# R40 register map
Vendor: Allwinner; Series: R40; File version: 0.1
CPU: CA7 0, little endian, MPU, FPU, double-precision FPU, 0 interrupt priority bits
Registers are 32-bit, read-write, reset 0x0 unless marked. A register's access mark holds for its fields unless they carry their own. Offsets are from the block's base; [hi:lo] are bit positions; lines under a group give offsets from that group; {n}, {i} and the like mark numbered series; 'fields as' and 'values as' point back to an identical list; <NAME> marks a mode.

## MP
Base 0x01E80000
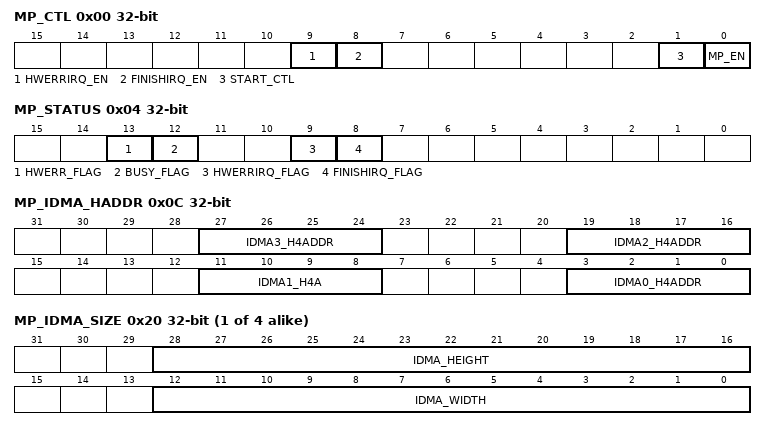
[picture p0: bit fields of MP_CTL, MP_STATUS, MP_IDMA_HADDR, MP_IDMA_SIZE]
0x00 MP_CTL
  [9] HWERRIRQ_EN — Hardware error IRQ enable control 0:Disable 1:Enable
  [8] FINISHIRQ_EN — Mission finish IRQ enable control 0:Disable 1:Enable
  [1] START_CTL — Start control If the bit is set, the module will start 1 frame operation and stop automatically.
  [0] MP_EN — Enable control 0:Disable 1:Enable
0x04 MP_STATUS
  [13] HWERR_FLAG ro — Hardware error status
  [12] BUSY_FLAG ro — Module working status 0:Idle 1:Running
  [9] HWERRIRQ_FLAG — Hardware error IRQ It will be set when hardware error occurs, and cleared by writing 1.
  [8] FINISHIRQ_FLAG — Mission finish IRQ It will be set when 1 frame operation accomplished, and cleared by writing 1.
0x08 MP_DMA_ORDER
  [9:8] MEMSCANORDER — Memory scan order selection 00: Top to down, Left to right 01: Top to down, Right to left 10: Down to top, Left to right 11: Down to top, Right to left Note: Four input DMA channel use the same scan rule. The each output DMA channel should match the same memory scan order rule with the input DMA channel.
    0=Top_to_down_comma__Left (Top to down, Left to right); 1=Top_to_down_comma__Right (Top to down, Right to left); 2=Down_to_top_comma__Left (Down to top, Left to right); 3=Down_to_top_comma__Right (Down to top, Right to left Note: Four input DMA channel use the same scan rule. The each output DMA channel should match the same memory scan order rule with the input DMA channel.)
0x0C MP_IDMA_HADDR
  [27:24] IDMA3_H4ADDR — High 4bit address in bit
  [19:16] IDMA2_H4ADDR — High 4bit address in bit
  [11:8] IDMA1_H4A — High 4bit address in bit
  [3:0] IDMA0_H4ADDR — High 4bit address in bit
{0x10+4i} _N[{i}] (i=0..3) group
  0x00 MP_IDMA_LADDR
    [31:0] IDMA_L32ADDR — Low 32bit address in bit
  0x10 MP_IDMA_PITCH
    [31:0] IDMA_PITCH — Pitch in bit
  0x20 MP_IDMA_SIZE
    [28:16] IDMA_HEIGHT — Memory block height in pixels The height = The value of these bits add 1
    [12:0] IDMA_WIDTH — Memory block width in pixels The width = The value of these bits add 1
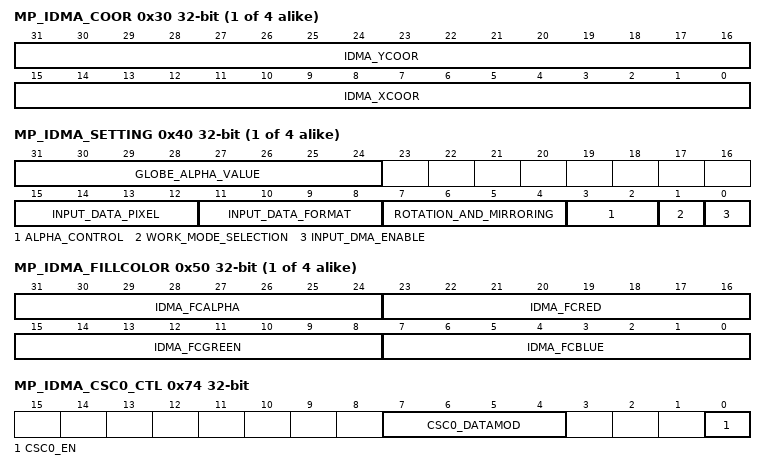
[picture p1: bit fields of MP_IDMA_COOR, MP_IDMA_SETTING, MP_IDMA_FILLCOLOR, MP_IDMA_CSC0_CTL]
  0x30 MP_IDMA_COOR
    [31:16] IDMA_YCOOR — Y coordinate Y is the left-top y coordinate of layer on output window in pixels The Y represent the two`s complement
    [15:0] IDMA_XCOOR — X coordinate X is left-top x coordinate of the layer on output window in pixels The X represent the two`s complement
  0x40 MP_IDMA_SETTING
    [31:24] GLOBE_ALPHA_VALUE
    [15:12] INPUT_DATA_PIXEL — Input data pixel sequence Reference input pixel sequence table
    [11:8] INPUT_DATA_FORMAT — Input data format 0000:32bpp - A8R8G8B8 or interleaved AYUV8888 0001:16bpp - A4R4G4B4 0010:16bpp - A1R5G5B5 0011:16bpp - R5G6B5 0100:16bpp - interleaved YUV422 0101:16bpp - U8V8 0110:8bpp - Y8 0111:8bpp - MONO or palette 1000:4bpp - MONO or palette 1001:2bpp - MONO or palette 1010:1bpp - MONO or palette Other: reserved Note: If the input data format is 16 or 32bpp, and the work mode is palette mode, only the low 8 bits input data is valid.
    [7:4] ROTATION_AND_MIRRORING — Rotation and mirroring control 0000:normal 0001:X 0010:Y 0011:XY 0100:A 0101:AX 0110:AY 0111:AXY Other: reserved
    [3:2] ALPHA_CONTROL — Alpha control 0:Ignore Output alpha value = pixels alpha, if no pixel alpha, the alpha value equal 0xff 01:Globe alpha enable Ignore pixel alpha value Output alpha value = globe alpha value 10: Globe alpha mix pixel alpha Output alpha value = globe alpha value * pixels alpha value 11:Reserved Note: The output alpha value here means the input alpha value of the ALU following the DMA controller.
      2=Globe alpha mix pixel alpha Output alpha value = globe alpha value * pixels alpha value 11:Reserved Note: The output alpha value here means the input alpha value of the ALU following the DMA controller
    [1] WORK_MODE_SELECTION — Work mode selection 0: normal mode ( non-palette mode ) 1: palette mode
      0=normal mode ( non-palette mode ); 1=palette_mode
    [0] INPUT_DMA_ENABLE — Input DMA enable control 0:disable input DMA channel, the respective fill-color value will stead of the input data. 1:enable
  0x50 MP_IDMA_FILLCOLOR
    [31:24] IDMA_FCALPHA — Alpha
    [23:16] IDMA_FCRED — Red
    [15:8] IDMA_FCGREEN — Green
    [7:0] IDMA_FCBLUE — Blue
0x74 MP_IDMA_CSC0_CTL
  [7:4] CSC0_DATAMOD — Data mode control 0000: Interleaved AYUV8888 mode 0001: Interleaved YUV422 mode In mode 0 and mode 1, only the channel 0 data path is valid for this module, the channel 1 data flow will by-pass the csc0 module, and direct to input formatter 1. 0010: Planar YUV422 mode (UV combined only) 0011: Planar YUV420 mode (UV combined only) 0100: Planar YUV411 mode (UV combined only) In mode 2/3/4, following rule: In this mode, the output data of the input formatter 1 will be stead of the respective fill-color value.
    0=Interleaved_AYUV8888_mode; 1=Interleaved YUV422 mode In mode 0 and mode 1, only the channel 0 data path is valid for this module, the channel 1 data flow will by-pass the csc0 module, and direct to input formatter 1; 2=Planar YUV422 mode (UV combined only); 3=Planar YUV420 mode (UV combined only); 4=Planar YUV411 mode (UV combined only) In mode 2/3/4, following rule: In this mode, the output data of the input formatter 1 will be stead of the respective fill-color value
  [0] CSC0_EN — Enable control 0: Disable color space function, ignore the control setting, and the data flow will by-pass the module. 1: Enable color space converting function.
    0=Disable color space function, ignore the control setting, and the data flow will by-pass the module; 1=Enable color space converting function
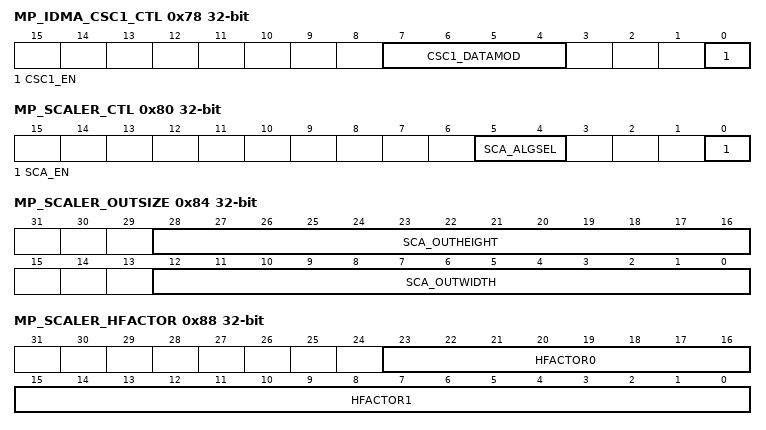
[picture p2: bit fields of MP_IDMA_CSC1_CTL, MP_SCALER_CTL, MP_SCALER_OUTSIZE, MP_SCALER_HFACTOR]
0x78 MP_IDMA_CSC1_CTL
  [7:4] CSC1_DATAMOD — Data mode control 0000: Interleaved AYUV8888 mode 0001: Interleaved YUV422 mode In mode 0 and mode 1, only the channel 3 data path is valid for this module, the channel 2 data flow will by-pass the csc1 module, and direct to input formatter 2. 0010: Planar YUV422 mode (UV combined only) 0011: Planar YUV420 mode (UV combined only) 0100: Planar YUV411 mode (UV combined only) In mode 2/3/4, following rule: In this mode, the output data of the input formatter 2 will be stead of the respective fill-color value.
    0=Interleaved_AYUV8888_mode; 1=Interleaved YUV422 mode In mode 0 and mode 1, only the channel 3 data path is valid for this module, the channel 2 data flow will by-pass the csc1 module, and direct to input formatter 2; 2=Planar YUV422 mode (UV combined only); 3=Planar YUV420 mode (UV combined only); 4=Planar YUV411 mode (UV combined only) In mode 2/3/4, following rule: In this mode, the output data of the input formatter 2 will be stead of the respective fill-color value
  [0] CSC1_EN — Enable control 0: Disable color space function, ignore the control setting, and the data flow will by-pass the module. 1: Enable color space converting function.
    values as MP_IDMA_CSC0_CTL.CSC0_EN
0x80 MP_SCALER_CTL
  [5:4] SCA_ALGSEL — Scaling algorithm selection 00: bi-cubic(4 taps in vertical and horizontal) 01: linear in vertical and bi-linear in horizontal(2 taps in vertical and 4 taps in horizontal) 10: extractive in vertical and bi-linear in horizontal(1 tap in vertical and 4 taps in horizontal) 11: Reserved
    0=bicubic_openingparen_4 (bi-cubic(4 taps in vertical and horizontal)); 1=linear in vertical and bi-linear in horizontal(2 taps in vertical and 4 taps in horizontal); 2=extractive in vertical and bi-linear in horizontal(1 tap in vertical and 4 taps in horizontal)
  [0] SCA_EN — Enable control 0: Disable scaler, ignore the whole scaling setting, and the data flow will by-pass the module. 1: Enable scaling function
    0=Disable scaler, ignore the whole scaling setting, and the data flow will by-pass the module; 1=Enable scaling function
0x84 MP_SCALER_OUTSIZE
  [28:16] SCA_OUTHEIGHT — Output height The output height = The value of these bits add 1 The minimum output height is 8 pixels.
  [12:0] SCA_OUTWIDTH — Output width The output width = The value of these bits add 1 The minimum output width is 16 pixels.
0x88 MP_SCALER_HFACTOR
  [23:16] HFACTOR0 — The integer part of the horizontal scaling ratio the horizontal scaling ratio = input width/output width
  [15:0] HFACTOR1 — The fractional part of the horizontal scaling ratio the horizontal scaling ratio = input width/output width The input width is the memory block width of respective iDMA channel.
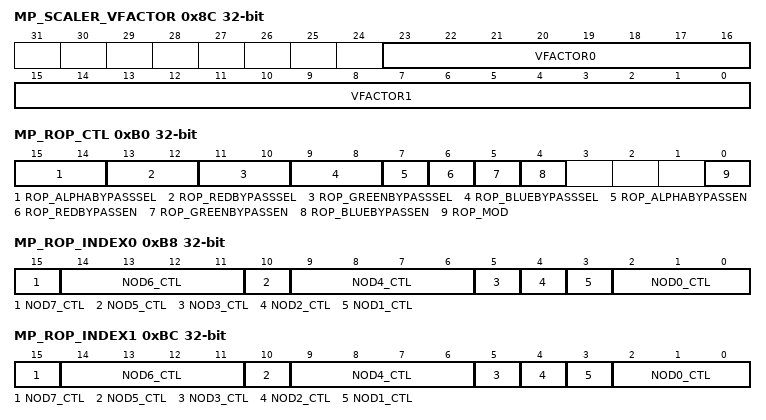
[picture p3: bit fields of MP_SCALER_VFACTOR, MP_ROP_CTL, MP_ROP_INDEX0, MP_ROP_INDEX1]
0x8C MP_SCALER_VFACTOR
  [23:16] VFACTOR0 — The integer part of the vertical scaling ratio the vertical scaling ratio = input height/output height
  [15:0] VFACTOR1 — The fractional part of the vertical scaling ratio the vertical scaling ratio = input height /output height The input height is the memory block height of respective iDMA channel.
0x90 MP_SCALER_HPHASE
  [19:0] HPHASE — Start phase in horizontal (complement) This value equals to start phase * 2
0x94 MP_SCALER_VPHASE
  [19:0] SCA_VERPHASE — Start phase in vertical (complement) This value equals to start phase * 2
0xB0 MP_ROP_CTL
  [15:14] ROP_ALPHABYPASSSEL — ROP output Alpha channel selection 00: Channel 0 01: Channel 1 10: Channel 2 11: Reserved The bit is only valid in by-pass mode of Alpha channel
    0=Channel_0; 1=Channel_1; 2=Channel_2
  [13:12] ROP_REDBYPASSSEL — ROP output Red channel selection 00: Channel 0 01: Channel 1 10: Channel 2 11: Reserved The bit is only valid in by-pass mode of Red channel
    0=Channel_0; 1=Channel_1; 2=Channel_2
  [11:10] ROP_GREENBYPASSSEL — ROP output Green channel selection 00: Channel 0 01: Channel 1 10: Channel 2 11: Reserved The bit is only valid in by-pass mode of Green channel
    0=Channel_0; 1=Channel_1; 2=Channel_2
  [9:8] ROP_BLUEBYPASSSEL — ROP output Blue channel selection 00: Channel 0 01: Channel 1 10: Channel 2 11: Reserved The bit is only valid in by-pass mode of Blue channel
    0=Channel_0; 1=Channel_1; 2=Channel_2
  [7] ROP_ALPHABYPASSEN — ROP Alpha channel by-pass enable control 0: Pass through 1: By-pass
    0=Pass through; 1=bypass
  [6] ROP_REDBYPASSEN — ROP Red channel by-pass enable control 0: Pass through 1: By-pass
    0=Pass through; 1=bypass
  [5] ROP_GREENBYPASSEN — ROP Green channel by-pass enable control 0: Pass through 1: By-pass
    0=Pass through; 1=bypass
  [4] ROP_BLUEBYPASSEN — ROP Blue channel by-pass enable control 0: Pass through 1: By-pass
    0=Pass through; 1=bypass
  [0] ROP_MOD — ROP type selection 0: ROP3 1: ROP4 In ROP3 mode, only the value of channel 3 index 0 control table setting register will be selected. In ROP3 mode, the channel 3 data will by-pass the ROP module. In ROP3 mode, the channel 3 data will direct to Alpha/CK module. In ROP4 mode, the respective input DMA channel fill color of channel 3 will transfer to Alpha/CK module.
    0=ROP3; 1=ROP4 (ROP4 In ROP3 mode, only the value of channel 3 index 0 control table setting register will be selected. In ROP3 mode, the channel 3 data will by-pass the ROP module. In ROP3 mode, the channel 3 data will direct to Alpha/CK module. In ROP4 mode, the respective input DMA channel fill color of channel 3 will transfer to Alpha/CK module.)
0xB8 MP_ROP_INDEX0
  [15] NOD7_CTL — Index 0 node7 setting ( channel 0` and channel 1` and channel 2` mix not logic ) 0: By-pass 1: Not
    0=bypass; 1=Not
  [14:11] NOD6_CTL — Index 0 node6 setting ( channel 0` and channel 1` and channel 2` mix logic ) 0000: And 0001: OR 0010: XOR 0011: Add in byte 0100: Add in word (32bit) 0101: Multiply in byte 0110: Multiply in word (32bit) 0111: Channel 0` mix channel 1` then sub channel 2` in byte 1000: Channel 0` mix channel 1` then sub channel 2` in word (32bit) Other: Reserved
  [10] NOD5_CTL — Index 0 node5 setting ( channel 0` and channel 1` mix not logic ) 0: By-pass 1: Not
    0=bypass; 1=Not
  [9:6] NOD4_CTL — Index 0 node4 setting ( channel 0` and channel 1` mix logic ) 0000: And 0001: OR 0010: XOR 0011: Add in byte 0100: Add in word (32bit) 0101: Multiply in byte 0110: Multiply in word (32bit) 0111: Channel 0` sub channel 1` in byte 1000: Channel 0` sub channel 1` in word (32bit) Other: Reserved
  [5] NOD3_CTL — Index 0 node3 setting ( channel 2` not logic ) 0: By-pass 1: Not
    0=bypass; 1=Not
  [4] NOD2_CTL — Index 0 node2 setting ( channel 1` not logic ) 0: By-pass 1: Not
    0=bypass; 1=Not
  [3] NOD1_CTL — Index 0 node1 setting ( channel 0` not logic) 0: By-pass 1: Not
    0=bypass; 1=Not
  [2:0] NOD0_CTL — Index 0 node0 setting ( sorting control ) 000: 012 001: 021 010: 102 011: 120 100: 201 101: 210 Other: Reserved
    0=_012; 1=_021; 2=_102; 3=_120; 4=_201; 5=210 Other: Reserved
0xBC MP_ROP_INDEX1
  [15] NOD7_CTL — Index 1 node7 setting ( channel 0` and channel 1` and channel 2` mix not logic ) 0: By-pass 1: Not
    0=bypass; 1=Not
  [14:11] NOD6_CTL — Index 1 node6 setting ( channel 0` and channel 1` and channel 2` mix logic ) 0000: And 0001: OR 0010: XOR 0011: Add in byte 0100: Add in word (32bit) 0101: Multiply in byte 0110: Multiply in word (32bit) 0111: Channel 0` mix channel 1` then sub channel 2` in byte 1000: Channel 0` mix channel 1` then sub channel 2` in word (32bit) Other: Reserved
  [10] NOD5_CTL — Index 1 node5 setting ( channel 0` and channel 1` mix not logic ) 0: By-pass 1: Not
    0=bypass; 1=Not
  [9:6] NOD4_CTL — Index 1 node4 setting ( channel 0` and channel 1` mix logic ) 0000: And 0001: OR 0010: XOR 0011: Add in byte 0100: Add in word (32bit) 0101: Multiply in byte 0110: Multiply in word (32bit) 0111: Channel 0` sub channel 1` in byte 1000: Channel 0` sub channel 1` in word (32bit) Other: Reserved
  [5] NOD3_CTL — Index 1 node3 setting ( channel 2` not logic ) 0: By-pass 1: Not
    0=bypass; 1=Not
  [4] NOD2_CTL — Index 1 node2 setting ( channel 1` not logic ) 0: By-pass 1: Not
    0=bypass; 1=Not
  [3] NOD1_CTL — Index 1 node1 setting ( channel 0` not logic) 0: By-pass 1: Not
    0=bypass; 1=Not
  [2:0] NOD0_CTL — Index 1 node0 setting ( sorting control ) 000: 012 001: 021 010: 102 011: 120 100: 201 101: 210 Other: Reserved
    values as MP_ROP_INDEX0.NOD0_CTL
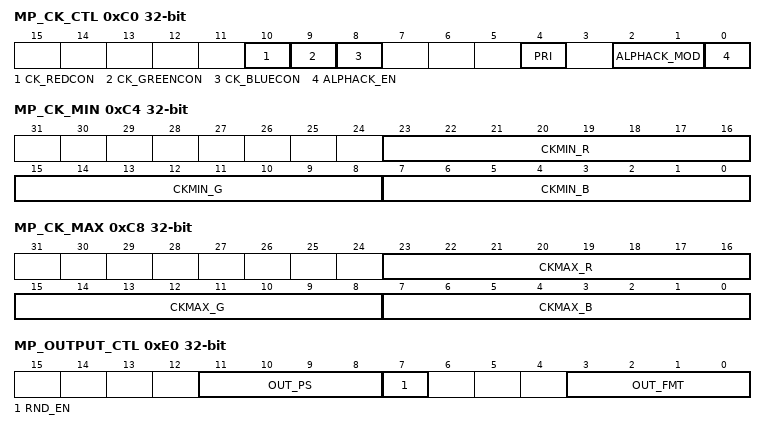
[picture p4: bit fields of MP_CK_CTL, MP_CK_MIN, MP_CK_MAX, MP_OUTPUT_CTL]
0xC0 MP_CK_CTL
  [10] CK_REDCON — Red control condition 0: If (R value of ck min color) <= (R value of layer0) <= (R value of ck max color), The red control condition is true, else the condition is false. 1: If (R value of ck min color) > (R value of layer0) or (R value of layer0) > (R value of ck max color), The red control condition is true, else the condition is false.
    0=If__openingparen_R_value_of_ck_min_color_closingparen___lt__equals_ (If (R value of ck min color) <= (R value of layer0) <= (R value of ck max color), The red control condition is true, else the condition is false.); 1=If__openingparen_R_value_of_ck_min_color_closingparen___gt_ (If (R value of ck min color) > (R value of layer0) or (R value of layer0) > (R value of ck max color), The red control condition is true, else the condition is false.)
  [9] CK_GREENCON — Green control condition 0: If (G value of ck min color) <= (G value of layer0) <= (G value of ck max color), The green control condition is true, else the condition is false. 1: If (G value of ck min color) > (G value of layer0) or (G value of layer0) > (G value of ck max color), The green control condition is true, else the condition is false.
    0=If__openingparen_G_value_of_ck_min_color_closingparen___lt__equals_ (If (G value of ck min color) <= (G value of layer0) <= (G value of ck max color), The green control condition is true, else the condition is false.); 1=If__openingparen_G_value_of_ck_min_color_closingparen___gt_ (If (G value of ck min color) > (G value of layer0) or (G value of layer0) > (G value of ck max color), The green control condition is true, else the condition is false.)
  [8] CK_BLUECON — Blue control condition 0: If (B value of ck min color) <= (B value of layer0) <= (B value of ck max color), The blue control condition is true, else the condition is false. 1: If (B value of ck min color) > (B value of layer0) or (B value of layer0) > (B value of ck max color), The blue control condition is true, else the condition is false.
    0=If__openingparen_B_value_of_ck_min_color_closingparen___lt__equals_ (If (B value of ck min color) <= (B value of layer0) <= (B value of ck max color), The blue control condition is true, else the condition is false.); 1=If__openingparen_B_value_of_ck_min_color_closingparen___gt_ (If (B value of ck min color) > (B value of layer0) or (B value of layer0) > (B value of ck max color), The blue control condition is true, else the condition is false.)
  [4] PRI — Priority selection 0: ROP output channel is higher than channel 3 1: Channel 3 is higher than ROP output channel
    0=ROP (ROP output channel is higher than channel 3); 1=Channel 3 is higher than ROP output channel
  [2:1] ALPHACK_MOD — Alpha / Color key mode selection 00: Alpha mode 01: Color key mode, using the high priority layer as matching condition, if it is true, the low priority layer pass. 10: color key mode, using the low priority layer as matching condition, if it is true, the high priority layer pass. 11: Reserved
  [0] ALPHACK_EN — Enable control 0: The ROP data will by-pass the alpha/ck module 1: Enable If the module is disabled, the data of channel 3 will be ignored, and only the ROP data will pass through to CSC2 module.
    0=ROP_data (The ROP data will by-pass the alpha/ck module); 1=Enable If the module is disabled, the data of channel 3 will be ignored, and only the ROP data will pass through to CSC2 module
0xC4 MP_CK_MIN
  [23:16] CKMIN_R — Red
  [15:8] CKMIN_G — Green
  [7:0] CKMIN_B — Blue
0xC8 MP_CK_MAX
  [23:16] CKMAX_R — Red
  [15:8] CKMAX_G — Green
  [7:0] CKMAX_B — Blue
0xD0 MP_CSC2_CTL
  [0] CSC2_EN — Enable control 0: Disable color space function, ignore the control setting, and the data flow will by-pass the module. 1: Enable color space converting function.
    values as MP_IDMA_CSC0_CTL.CSC0_EN
0xE0 MP_OUTPUT_CTL
  [11:8] OUT_PS — Output data pixel sequence Reference output pixel sequence table
  [7] RND_EN — Round enable 0: Disabled 1: Enabled
    0=Disabled; 1=Enabled
  [3:0] OUT_FMT — Output data format 0000: 32bpp - A8R8G8B8 or interleaved AYUV8888 0001: 16bpp - A4R4G4B4 0010: 16bpp - A1R5G5B5 0011: 16bpp - R5G6B5 0100: 16bpp - interleaved YUV422 0101: planar YUV422 (UV combined) 0110: planar YUV422 0111: 8bpp - MONO 1000: 4bpp - MONO 1001: 2bpp - MONO 1010: 1bpp - MONO 1011: planar YUV420 (UV combined) 1100: planar YUV420 1101: planar YUV411 (UV combined) 1110: planar YUV411 Other: Reserved Note: In all YUV output data format, the CSC2 must be enabled, otherwise the output data mode will be 32bpp A8R8G8B8 mode.
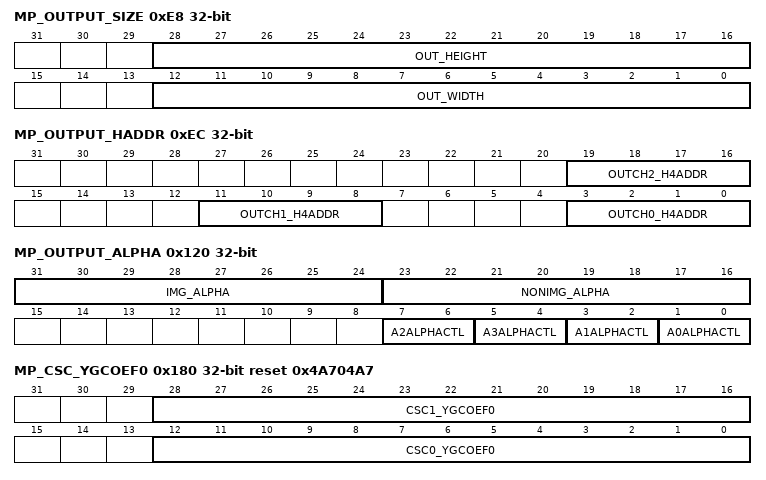
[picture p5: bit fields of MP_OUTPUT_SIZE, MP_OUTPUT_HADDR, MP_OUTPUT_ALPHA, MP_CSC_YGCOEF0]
0xE8 MP_OUTPUT_SIZE
  [28:16] OUT_HEIGHT — Height The value add 1 equal the actual output image height
  [12:0] OUT_WIDTH — Width The value add 1 equal the actual output image width
0xEC MP_OUTPUT_HADDR
  [19:16] OUTCH2_H4ADDR — Output channel 2 High 4bit address in bit
  [11:8] OUTCH1_H4ADDR — Output channel 1 High 4bit address in bit
  [3:0] OUTCH0_H4ADDR — Output channel 0 High 4bit address in bit
{0xF0+4i} _N[{i}] (i=0..2) group
  0x00 MP_OUTPUT_LADDR
    [31:0] OUT_L32ADDR — Output channel Low 32bit address in bit
  0x10 MP_OUTPUT_PITCH
    [31:0] OUT_LINEWIDTH — Output channel Pitch in bit
  0xD0 MP_OCSC_YGCOEF
    [12:0] CSC2_YGCOEF — The Y/G coefficient The value equals to coefficient*2
  0xE0 MP_OCSC_URCOEF
    [12:0] CSC2_URCOEF — The U/R coefficient The value equals to coefficient*2
  0xF0 MP_OCSC_VBCOEF
    [12:0] CSC2_VBCOEF — The V/B coefficient The value equals to coefficient*2
0x120 MP_OUTPUT_ALPHA
  [31:24] IMG_ALPHA — Output image area alpha value, the image area include A0,A1 and overlapping area A2.
  [23:16] NONIMG_ALPHA — Output non-image area alpha value, the non-image area means the pure fill color area.
  [7:6] A2ALPHACTL — A2 area alpha value control 00: using A0 self pixel alpha (A0pA) 01: using A1 self pixel alpha (A1pA) 10: the alpha value = A0pA + A1pA * ( 1 - A0pA ) 11: using the Output image area alpha value (bit31:24)
    0=A0 (using A0 self pixel alpha (A0pA)); 1=A1 (using A1 self pixel alpha (A1pA)); 2=alpha (the alpha value = A0pA + A1pA * ( 1 - A0pA )); 3=Output (using the Output image area alpha value (bit31:24))
  [5:4] A3ALPHACTL — A3 area alpha value control 00: 0xff 01: using the Output non-image area alpha value (bit23:16) Other: reserved
    0=_0xff; 1=Output (using the Output non-image area alpha value (bit23:16) Other: reserved)
  [3:2] A1ALPHACTL — A1 area alpha value control 00: using A1 self pixel alpha 01: using the Output image area alpha value (bit31:24) Other: reserved
    0=A1 (using A1 self pixel alpha); 1=Output (using the Output image area alpha value (bit31:24) Other: reserved)
  [1:0] A0ALPHACTL — A0 area alpha value control 00: using A0 self pixel alpha 01: using the Output image area alpha value (bit31:24) Other: reserved
    0=A0 (using A0 self pixel alpha); 1=Output (using the Output image area alpha value (bit31:24) Other: reserved)
0x180 MP_CSC_YGCOEF0 reset 0x4A704A7
  [28:16] CSC1_YGCOEF0 — The Y/G coefficient for CSC1 The value equals to coefficient*2
  [12:0] CSC0_YGCOEF0 — The Y/G coefficient for CSC0 The value equals to coefficient*2
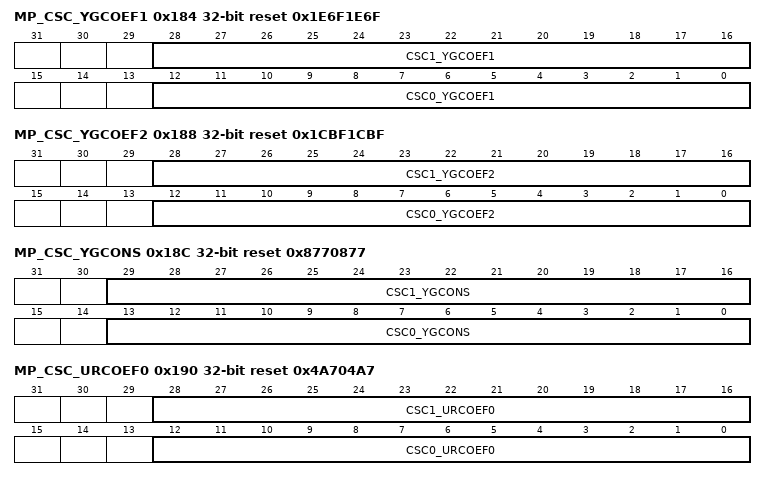
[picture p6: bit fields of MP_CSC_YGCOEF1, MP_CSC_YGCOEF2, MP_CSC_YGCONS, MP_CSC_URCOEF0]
0x184 MP_CSC_YGCOEF1 reset 0x1E6F1E6F
  [28:16] CSC1_YGCOEF1 — The Y/G coefficient for CSC1 The value equals to coefficient*2
  [12:0] CSC0_YGCOEF1 — The Y/G coefficient for CSC0 The value equals to coefficient*2
0x188 MP_CSC_YGCOEF2 reset 0x1CBF1CBF
  [28:16] CSC1_YGCOEF2 — The Y/G coefficient for CSC1 The value equals to coefficient*2
  [12:0] CSC0_YGCOEF2 — The Y/G coefficient for CSC0 The value equals to coefficient*2
0x18C MP_CSC_YGCONS reset 0x8770877
  [29:16] CSC1_YGCONS — The Y/G constant for CSC1 The value equals to coefficient*2
  [13:0] CSC0_YGCONS — The Y/G constant for CSC0 The value equals to coefficient*2
0x190 MP_CSC_URCOEF0 reset 0x4A704A7
  [28:16] CSC1_URCOEF0 — The U/R coefficient for CSC1 The value equals to coefficient*2
  [12:0] CSC0_URCOEF0 — The U/R coefficient for CSC0 The value equals to coefficient*2
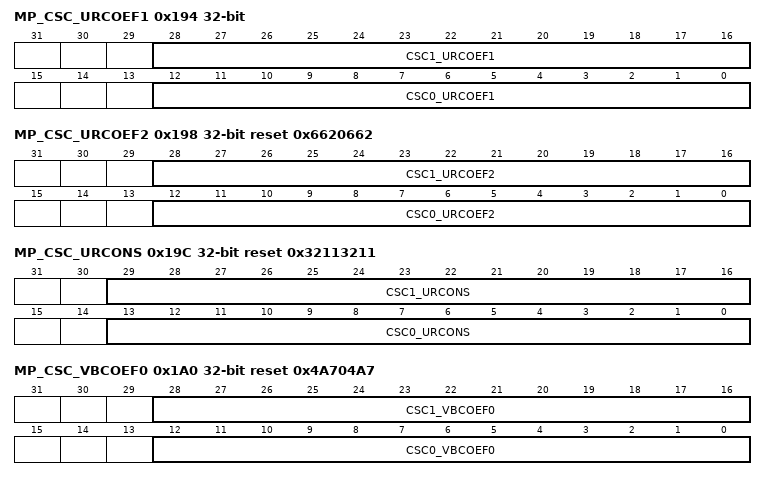
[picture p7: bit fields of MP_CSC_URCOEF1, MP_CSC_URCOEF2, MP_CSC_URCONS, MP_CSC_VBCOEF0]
0x194 MP_CSC_URCOEF1
  [28:16] CSC1_URCOEF1 — The U/R coefficient for CSC1 The value equals to coefficient*2
  [12:0] CSC0_URCOEF1 — The U/R coefficient for CSC0 The value equals to coefficient*2
0x198 MP_CSC_URCOEF2 reset 0x6620662
  [28:16] CSC1_URCOEF2 — The U/R coefficient for CSC1 The value equals to coefficient*2
  [12:0] CSC0_URCOEF2 — The U/R coefficient for CSC0 The value equals to coefficient*2
0x19C MP_CSC_URCONS reset 0x32113211
  [29:16] CSC1_URCONS — The U/R constant for CSC1 The value equals to coefficient*2
  [13:0] CSC0_URCONS — The U/R constant for CSC0 The value equals to coefficient*2
0x1A0 MP_CSC_VBCOEF0 reset 0x4A704A7
  [28:16] CSC1_VBCOEF0 — The V/B coefficient for CSC1 The value equals to coefficient*2
  [12:0] CSC0_VBCOEF0 — The V/B coefficient for CSC0 The value equals to coefficient*2
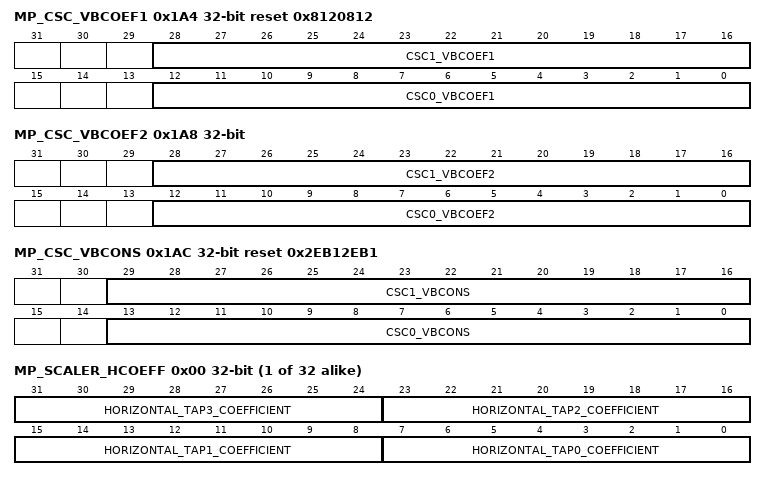
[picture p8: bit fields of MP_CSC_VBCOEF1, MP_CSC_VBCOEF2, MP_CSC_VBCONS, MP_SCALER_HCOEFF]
0x1A4 MP_CSC_VBCOEF1 reset 0x8120812
  [28:16] CSC1_VBCOEF1 — The V/B coefficient for CSC1 The value equals to coefficient*2
  [12:0] CSC0_VBCOEF1 — The V/B coefficient for CSC0 The value equals to coefficient*2
0x1A8 MP_CSC_VBCOEF2
  [28:16] CSC1_VBCOEF2 — the V/B coefficient for CSC1 the value equals to coefficient*2
  [12:0] CSC0_VBCOEF2 — the V/B coefficient for CSC0 the value equals to coefficient*2
0x1AC MP_CSC_VBCONS reset 0x2EB12EB1
  [29:16] CSC1_VBCONS — The V/B constant for CSC1 The value equals to coefficient*2
  [13:0] CSC0_VBCONS — The V/B constant for CSC0 The value equals to coefficient*2
0x1CC MP_OCSC_YGCONS
  [13:0] CSC2_YGCONS — The Y/G constant The value equals to coefficient*2
0x1DC MP_OCSC_URCONS
  [13:0] CSC2_URCONS — The U/R constant The value equals to coefficient*2
0x1EC MP_OCSC_VBCONS
  [13:0] CSC2_VBCONS — The V/B constant The value equals to coefficient*2
{0x200+4i} _N[{i}] (i=0..31) group
  0x00 MP_SCALER_HCOEFF
    [8n+7:8n] HORIZONTAL_TAP{n}_COEFFICIENT (n=0..3) — Horizontal tap{n} coefficient The value equals to coefficient*2
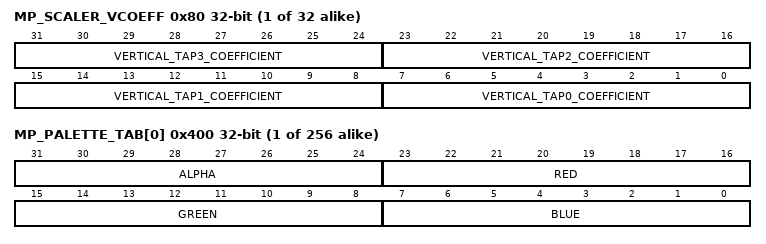
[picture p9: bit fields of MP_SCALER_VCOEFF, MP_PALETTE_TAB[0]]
  0x80 MP_SCALER_VCOEFF
    [8n+7:8n] VERTICAL_TAP{n}_COEFFICIENT (n=0..3) — Vertical tap{n} coefficient The value equals to coefficient*2
{0x400+4i} MP_PALETTE_TAB[{i}] (i=0..255) reset not defined — MP_PALETTE_TAB[{i}]
  [31:24] ALPHA — Alpha value
  [23:16] RED — Red value
  [15:8] GREEN — Green value
  [7:0] BLUE — Blue value
